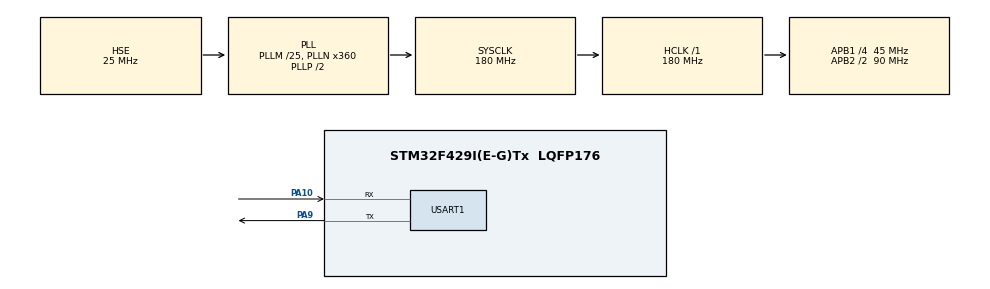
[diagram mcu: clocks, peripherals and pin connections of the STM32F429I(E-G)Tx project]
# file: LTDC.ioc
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ADC1.Channel-0\#ChannelRegularConversion=ADC_CHANNEL_TEMPSENSOR
ADC1.InjNumberOfConversion=0
ADC1.NbrOfConversionFlag=1
ADC1.Rank-0\#ChannelRegularConversion=1
ADC1.SamplingTime-0\#ChannelRegularConversion=ADC_SAMPLETIME_3CYCLES
ADC1.master=1
Dma.ADC1.0.Direction=DMA_PERIPH_TO_MEMORY
Dma.ADC1.0.FIFOMode=DMA_FIFOMODE_DISABLE
Dma.ADC1.0.Instance=DMA2_Stream0
Dma.ADC1.0.MemDataAlignment=DMA_MDATAALIGN_HALFWORD
Dma.ADC1.0.MemInc=DMA_MINC_ENABLE
Dma.ADC1.0.Mode=DMA_CIRCULAR
Dma.ADC1.0.PeriphDataAlignment=DMA_PDATAALIGN_HALFWORD
Dma.ADC1.0.PeriphInc=DMA_PINC_DISABLE
Dma.ADC1.0.Priority=DMA_PRIORITY_LOW
Dma.Request0=ADC1
Mcu.Family=STM32F4
Mcu.Name=STM32F429I(E-G)Tx
Mcu.Package=LQFP176
NVIC.DMA2_Stream0_IRQn=true\:0\:0\:false\:false\:true\:false\:true\:true
NVIC.PriorityGroup=NVIC_PRIORITYGROUP_4
NVIC.TIM6_DAC_IRQn=true\:0\:0\:false\:false\:true\:true\:true\:true
NVIC.USART1_IRQn=true\:0\:0\:false\:false\:true\:true\:true\:true
PA10.Mode=Asynchronous
PA10.Signal=USART1_RX
PA9.GPIO_PuPd=GPIO_PULLUP
PA9.Mode=Asynchronous
PA9.Signal=USART1_TX
PC14/OSC32_IN.Mode=LSE-External-Oscillator
PC14/OSC32_IN.Signal=RCC_OSC32_IN
PC15/OSC32_OUT.Mode=LSE-External-Oscillator
PC15/OSC32_OUT.Signal=RCC_OSC32_OUT
PH0/OSC_IN.Mode=HSE-External-Oscillator
PH0/OSC_IN.Signal=RCC_OSC_IN
PH1/OSC_OUT.Mode=HSE-External-Oscillator
PH1/OSC_OUT.Signal=RCC_OSC_OUT
ProjectManager.HeapSize=0x200
ProjectManager.StackSize=0x400
ProjectManager.TargetToolchain=EWARM V8.50
RCC.48MHZClocksFreq_Value=90000000
RCC.AHBFreq_Value=180000000
RCC.APB1CLKDivider=RCC_HCLK_DIV4
RCC.APB1Freq_Value=45000000
RCC.APB1TimFreq_Value=90000000
RCC.APB2CLKDivider=RCC_HCLK_DIV2
RCC.APB2Freq_Value=90000000
RCC.APB2TimFreq_Value=180000000
RCC.CortexFreq_Value=180000000
RCC.HCLKFreq_Value=180000000
RCC.HSE_VALUE=25000000
RCC.HSI_VALUE=16000000
RCC.PLLM=25
RCC.PLLN=360
RCC.PLLSourceVirtual=RCC_PLLSOURCE_HSE
RCC.SYSCLKFreq_VALUE=180000000
RCC.SYSCLKSource=RCC_SYSCLKSOURCE_PLLCLK
RCC.VCOOutputFreq_Value=360000000
TIM6.Period=9000-1
TIM6.Prescaler=10-1
USART1.VirtualMode=VM_ASYNC
VP_ADC1_TempSens_Input.Mode=IN-TempSens
VP_TIM6_VS_ClockSourceINT.Mode=Enable_Timer
board=custom

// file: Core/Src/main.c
/* USER CODE BEGIN Header */
/**
  ******************************************************************************
  * @file           : main.c
  * @brief          : Main program body
  ******************************************************************************
  * @attention
  *
  * Copyright (c) 2025 STMicroelectronics.
  * All rights reserved.
  *
  * This software is licensed under terms that can be found in the LICENSE file
  * in the root directory of this software component.
  * If no LICENSE file comes with this software, it is provided AS-IS.
  *
  ******************************************************************************
  */
/* USER CODE END Header */
#include "main.h"
#include "adc.h"
#include "dma.h"
#include "tim.h"
#include "usart.h"
#include "gpio.h"

/* USER CODE BEGIN Includes */
#include "sys.h"
#include "delay.h"
#include "led.h"
#include "key.h"
#include "ltdc.h"
#include "lcd.h"
#include "sdram.h"
#include "lvgl.h"
#include "lv_port_disp_template.h"
/* USER CODE END Includes */

void SystemClock_Config(void);

int main(void)
{

  /* USER CODE BEGIN 1 */
  uint8_t lcd_id[20];
  /* USER CODE END 1 */

  /* MCU Configuration--------------------------------------------------------*/

  /* Reset of all peripherals, Initializes the Flash interface and the Systick. */
  HAL_Init();

  /* USER CODE BEGIN Init */
  delay_init(180);
  led_init();
  key_init();
  sdram_init();
  lcd_init();
  lv_init();    /* 初始化LVGL图形库 */
  lv_port_disp_init();    /* 注册设备 */
  /* USER CODE END Init */

  /* Configure the system clock */
  SystemClock_Config();

  /* Initialize all configured peripherals */
  MX_GPIO_Init();
  MX_DMA_Init();
  MX_USART1_UART_Init();
  MX_ADC1_Init();
  MX_TIM6_Init();
  /* USER CODE BEGIN 2 */
  sprintf((char *)lcd_id, "LCD ID is %04x", lcddev.id);
  double ic_temp;
  uint8_t txbuf[40];

  lv_obj_t *label = lv_label_create(lv_scr_act());
  lv_label_set_text(label, "STM32F429 LVGL DEVICE TEST");
  lv_obj_center(label);
  lv_obj_set_style_text_font(label, &lv_font_montserrat_32, 0);
  /* USER CODE END 2 */

  /* Infinite loop */
  while (1)
  {

    /* USER CODE BEGIN 3 */
    lv_timer_handler();
    delay_ms(5);
  }
  /* USER CODE END 3 */
}

void SystemClock_Config(void)
{
  RCC_OscInitTypeDef RCC_OscInitStruct = {0};
  RCC_ClkInitTypeDef RCC_ClkInitStruct = {0};

  /** Configure the main internal regulator output voltage
  */
  __HAL_RCC_PWR_CLK_ENABLE();
  __HAL_PWR_VOLTAGESCALING_CONFIG(PWR_REGULATOR_VOLTAGE_SCALE1);

  /** Initializes the RCC Oscillators according to the specified parameters
  * in the RCC_OscInitTypeDef structure.
  */
  RCC_OscInitStruct.OscillatorType = RCC_OSCILLATORTYPE_HSE;
  RCC_OscInitStruct.HSEState = RCC_HSE_ON;
  RCC_OscInitStruct.PLL.PLLState = RCC_PLL_ON;
  RCC_OscInitStruct.PLL.PLLSource = RCC_PLLSOURCE_HSE;
  RCC_OscInitStruct.PLL.PLLM = 25;
  RCC_OscInitStruct.PLL.PLLN = 360;
  RCC_OscInitStruct.PLL.PLLP = RCC_PLLP_DIV2;
  RCC_OscInitStruct.PLL.PLLQ = 4;
  if (HAL_RCC_OscConfig(&RCC_OscInitStruct) != HAL_OK)
  {
    Error_Handler();
  }

  /** Activate the Over-Drive mode
  */
  if (HAL_PWREx_EnableOverDrive() != HAL_OK)
  {
    Error_Handler();
  }

  /** Initializes the CPU, AHB and APB buses clocks
  */
  RCC_ClkInitStruct.ClockType = RCC_CLOCKTYPE_HCLK|RCC_CLOCKTYPE_SYSCLK
                              |RCC_CLOCKTYPE_PCLK1|RCC_CLOCKTYPE_PCLK2;
  RCC_ClkInitStruct.SYSCLKSource = RCC_SYSCLKSOURCE_PLLCLK;
  RCC_ClkInitStruct.AHBCLKDivider = RCC_SYSCLK_DIV1;
  RCC_ClkInitStruct.APB1CLKDivider = RCC_HCLK_DIV4;
  RCC_ClkInitStruct.APB2CLKDivider = RCC_HCLK_DIV2;

  if (HAL_RCC_ClockConfig(&RCC_ClkInitStruct, FLASH_LATENCY_5) != HAL_OK)
  {
    Error_Handler();
  }
}

void Error_Handler(void)
{
  __disable_irq();
  while (1)
  {
  }
}
